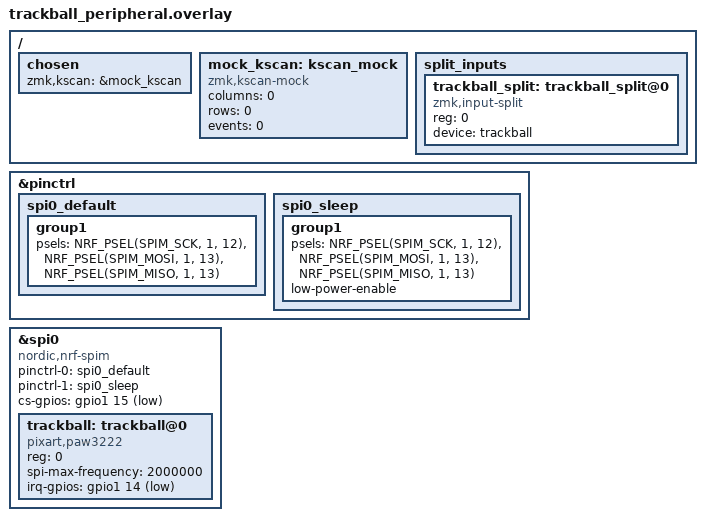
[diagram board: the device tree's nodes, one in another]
/ {
    chosen {
        zmk,kscan = &mock_kscan;
    };

    mock_kscan: kscan_mock {
        compatible = "zmk,kscan-mock";
        columns = <0>;
        rows = <0>;
        events = <0>;
    };

    // Split input: forwards trackball movement to the central (dongle) over BLE
    split_inputs {
        #address-cells = <1>;
        #size-cells = <0>;

        trackball_split: trackball_split@0 {
            compatible = "zmk,input-split";
            reg = <0>;
            device = <&trackball>;
        };
    };
};

&pinctrl {
    spi0_default: spi0_default {
        group1 {
            psels = <NRF_PSEL(SPIM_SCK, 1, 12)>,    // D7 = P1.12 (SCLK)
                    <NRF_PSEL(SPIM_MOSI, 1, 13)>,   // D8 = P1.13 (SDIO)
                    <NRF_PSEL(SPIM_MISO, 1, 13)>;   // D8 = P1.13 (SDIO shared)
        };
    };

    spi0_sleep: spi0_sleep {
        group1 {
            psels = <NRF_PSEL(SPIM_SCK, 1, 12)>,
                    <NRF_PSEL(SPIM_MOSI, 1, 13)>,
                    <NRF_PSEL(SPIM_MISO, 1, 13)>;
            low-power-enable;
        };
    };
};

&spi0 {
    status = "okay";
    compatible = "nordic,nrf-spim";
    pinctrl-0 = <&spi0_default>;
    pinctrl-1 = <&spi0_sleep>;
    pinctrl-names = "default", "sleep";
    cs-gpios = <&gpio1 15 GPIO_ACTIVE_LOW>;   // D10 = P1.15 (CS)

    trackball: trackball@0 {
        status = "okay";
        compatible = "pixart,paw3222";
        reg = <0>;
        spi-max-frequency = <2000000>;
        irq-gpios = <&gpio1 14 (GPIO_ACTIVE_LOW | GPIO_PULL_UP)>;  // D9 = P1.14 (MOTION)
    };
};
